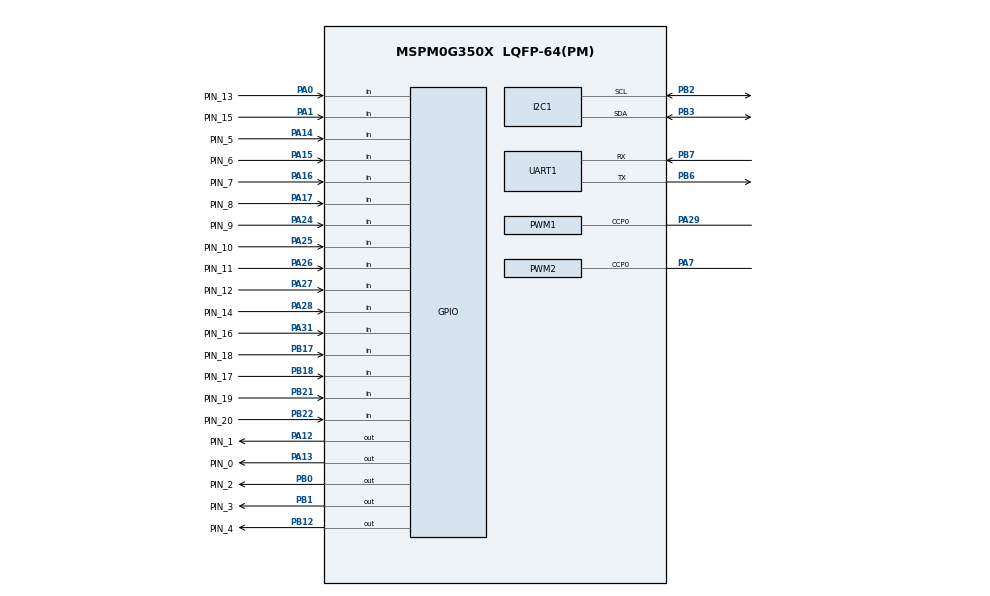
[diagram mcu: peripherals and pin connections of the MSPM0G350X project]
/**
 * @cliArgs --device "MSPM0G350X" --part "Default" --package "LQFP-64(PM)" --product "mspm0_sdk@2.10.00.04"
 * @versions {"tool":"1.26.2+4477"}
 */

/**
 * Import the modules used in this configuration.
 */
const GPIO   = scripting.addModule("/ti/driverlib/GPIO", {}, false);
const GPIO1  = GPIO.addInstance();
const GPIO2  = GPIO.addInstance();
const GPIO3  = GPIO.addInstance();
const GPIO4  = GPIO.addInstance();
const GPIO5  = GPIO.addInstance();
const GPIO6  = GPIO.addInstance();
const GPIO7  = GPIO.addInstance();
const GPIO8  = GPIO.addInstance();
const GPIO9  = GPIO.addInstance();
const GPIO10 = GPIO.addInstance();
const GPIO11 = GPIO.addInstance();
const GPIO12 = GPIO.addInstance();
const GPIO13 = GPIO.addInstance();
const GPIO14 = GPIO.addInstance();
const GPIO15 = GPIO.addInstance();
const GPIO16 = GPIO.addInstance();
const GPIO17 = GPIO.addInstance();
const GPIO18 = GPIO.addInstance();
const GPIO19 = GPIO.addInstance();
const GPIO20 = GPIO.addInstance();
const GPIO21 = GPIO.addInstance();
const I2C    = scripting.addModule("/ti/driverlib/I2C", {}, false);
const I2C1   = I2C.addInstance();
const PWM    = scripting.addModule("/ti/driverlib/PWM", {}, false);
const PWM1   = PWM.addInstance();
const PWM2   = PWM.addInstance();
const SYSCTL = scripting.addModule("/ti/driverlib/SYSCTL");
const UART   = scripting.addModule("/ti/driverlib/UART", {}, false);
const UART1  = UART.addInstance();

/**
 * Write custom configuration values to the imported modules.
 */
GPIO1.$name                         = "MOTOR_AIN2";
GPIO1.port                          = "PORTA";
GPIO1.associatedPins[0].$name       = "PIN_0";
GPIO1.associatedPins[0].pin.$assign = "PA13";

const Board = scripting.addModule("/ti/driverlib/Board", {}, false);

GPIO2.$name                         = "MOTOR_AIN1";
GPIO2.port                          = "PORTA";
GPIO2.associatedPins[0].$name       = "PIN_1";
GPIO2.associatedPins[0].pin.$assign = "PA12";

GPIO3.$name                         = "MOTOR_BIN1";
GPIO3.port                          = "PORTB";
GPIO3.associatedPins[0].$name       = "PIN_2";
GPIO3.associatedPins[0].pin.$assign = "PB0";

GPIO4.$name                         = "MOTOR_BIN2";
GPIO4.port                          = "PORTB";
GPIO4.associatedPins[0].$name       = "PIN_3";
GPIO4.associatedPins[0].pin.$assign = "PB1";

GPIO5.$name                         = "MOTOR_STBY";
GPIO5.port                          = "PORTB";
GPIO5.associatedPins[0].$name       = "PIN_4";
GPIO5.associatedPins[0].pin.$assign = "PB12";

GPIO6.$name                         = "SENSOR_S0";
GPIO6.port                          = "PORTA";
GPIO6.associatedPins[0].$name       = "PIN_5";
GPIO6.associatedPins[0].direction   = "INPUT";
GPIO6.associatedPins[0].pin.$assign = "PA14";

GPIO7.$name                         = "SENSOR_S1";
GPIO7.port                          = "PORTA";
GPIO7.associatedPins[0].$name       = "PIN_6";
GPIO7.associatedPins[0].direction   = "INPUT";
GPIO7.associatedPins[0].pin.$assign = "PA15";

GPIO8.$name                         = "SENSOR_S2";
GPIO8.port                          = "PORTA";
GPIO8.associatedPins[0].$name       = "PIN_7";
GPIO8.associatedPins[0].direction   = "INPUT";
GPIO8.associatedPins[0].pin.$assign = "PA16";

GPIO9.$name                         = "SENSOR_S3";
GPIO9.port                          = "PORTA";
GPIO9.associatedPins[0].$name       = "PIN_8";
GPIO9.associatedPins[0].direction   = "INPUT";
GPIO9.associatedPins[0].pin.$assign = "PA17";

GPIO10.$name                         = "SENSOR_S4";
GPIO10.port                          = "PORTA";
GPIO10.associatedPins[0].$name       = "PIN_9";
GPIO10.associatedPins[0].direction   = "INPUT";
GPIO10.associatedPins[0].pin.$assign = "PA24";

GPIO11.$name                         = "SENSOR_S5";
GPIO11.port                          = "PORTA";
GPIO11.associatedPins[0].$name       = "PIN_10";
GPIO11.associatedPins[0].direction   = "INPUT";
GPIO11.associatedPins[0].pin.$assign = "PA25";

GPIO12.$name                         = "SENSOR_S6";
GPIO12.port                          = "PORTA";
GPIO12.associatedPins[0].$name       = "PIN_11";
GPIO12.associatedPins[0].direction   = "INPUT";
GPIO12.associatedPins[0].pin.$assign = "PA26";

GPIO13.$name                         = "SENSOR_S7";
GPIO13.port                          = "PORTA";
GPIO13.associatedPins[0].$name       = "PIN_12";
GPIO13.associatedPins[0].direction   = "INPUT";
GPIO13.associatedPins[0].pin.$assign = "PA27";

GPIO14.$name                         = "SENSOR_S8";
GPIO14.port                          = "PORTA";
GPIO14.associatedPins[0].$name       = "PIN_13";
GPIO14.associatedPins[0].direction   = "INPUT";
GPIO14.associatedPins[0].pin.$assign = "PA0";

GPIO15.$name                         = "SENSOR_S9";
GPIO15.port                          = "PORTA";
GPIO15.associatedPins[0].$name       = "PIN_14";
GPIO15.associatedPins[0].direction   = "INPUT";
GPIO15.associatedPins[0].pin.$assign = "PA28";

GPIO16.$name                         = "SENSOR_S10";
GPIO16.port                          = "PORTA";
GPIO16.associatedPins[0].$name       = "PIN_15";
GPIO16.associatedPins[0].direction   = "INPUT";
GPIO16.associatedPins[0].pin.$assign = "PA1";

GPIO17.$name                         = "SENSOR_S11";
GPIO17.port                          = "PORTA";
GPIO17.associatedPins[0].$name       = "PIN_16";
GPIO17.associatedPins[0].direction   = "INPUT";
GPIO17.associatedPins[0].pin.$assign = "PA31";

GPIO18.$name                                 = "ENC_LEFT_A";
GPIO18.port                                  = "PORTB";
GPIO18.associatedPins[0].$name               = "PIN_17";
GPIO18.associatedPins[0].direction           = "INPUT";
GPIO18.associatedPins[0].assignedPortSegment = "Upper";
GPIO18.associatedPins[0].pin.$assign         = "PB18";

GPIO19.$name                                 = "ENC_LEFT_B";
GPIO19.port                                  = "PORTB";
GPIO19.associatedPins[0].$name               = "PIN_18";
GPIO19.associatedPins[0].direction           = "INPUT";
GPIO19.associatedPins[0].assignedPortSegment = "Upper";
GPIO19.associatedPins[0].pin.$assign         = "PB17";

GPIO20.$name                                 = "ENC_RIGHT_A";
GPIO20.port                                  = "PORTB";
GPIO20.associatedPins[0].$name               = "PIN_19";
GPIO20.associatedPins[0].direction           = "INPUT";
GPIO20.associatedPins[0].assignedPortSegment = "Upper";
GPIO20.associatedPins[0].pin.$assign         = "PB21";

GPIO21.$name                                 = "ENC_RIGHT_B";
GPIO21.port                                  = "PORTB";
GPIO21.associatedPins[0].$name               = "PIN_20";
GPIO21.associatedPins[0].direction           = "INPUT";
GPIO21.associatedPins[0].assignedPortSegment = "Upper";
GPIO21.associatedPins[0].pin.$assign         = "PB22";

I2C1.$name                             = "I2C_Sensor";
I2C1.basicEnableController             = true;
I2C1.basicControllerStandardBusSpeed   = "Fast";
I2C1.peripheral.sdaPin.$assign         = "PB3";
I2C1.peripheral.sclPin.$assign         = "PB2";
I2C1.sdaPinConfig.hideOutputInversion  = scripting.forceWrite(false);
I2C1.sdaPinConfig.onlyInternalResistor = scripting.forceWrite(false);
I2C1.sdaPinConfig.passedPeripheralType = scripting.forceWrite("Digital");
I2C1.sdaPinConfig.$name                = "ti_driverlib_gpio_GPIOPinGeneric4";
I2C1.sclPinConfig.hideOutputInversion  = scripting.forceWrite(false);
I2C1.sclPinConfig.onlyInternalResistor = scripting.forceWrite(false);
I2C1.sclPinConfig.passedPeripheralType = scripting.forceWrite("Digital");
I2C1.sclPinConfig.$name                = "ti_driverlib_gpio_GPIOPinGeneric5";

PWM1.$name                              = "MotorPWM_Left";
PWM1.timerCount                         = 1600;
PWM1.ccIndex                            = [0];
PWM1.PWM_CHANNEL_0.$name                = "ti_driverlib_pwm_PWMTimerCC0";
PWM1.ccp0PinConfig.direction            = scripting.forceWrite("OUTPUT");
PWM1.ccp0PinConfig.hideOutputInversion  = scripting.forceWrite(false);
PWM1.ccp0PinConfig.onlyInternalResistor = scripting.forceWrite(false);
PWM1.ccp0PinConfig.passedPeripheralType = scripting.forceWrite("Digital");
PWM1.ccp0PinConfig.$name                = "ti_driverlib_gpio_GPIOPinGeneric0";
PWM1.peripheral.ccp0Pin.$assign         = "PA29";

PWM2.$name                              = "MotorPWM_Right";
PWM2.timerCount                         = 1600;
PWM2.ccIndex                            = [0];
PWM2.PWM_CHANNEL_0.$name                = "ti_driverlib_pwm_PWMTimerCC1";
PWM2.ccp0PinConfig.direction            = scripting.forceWrite("OUTPUT");
PWM2.ccp0PinConfig.hideOutputInversion  = scripting.forceWrite(false);
PWM2.ccp0PinConfig.onlyInternalResistor = scripting.forceWrite(false);
PWM2.ccp0PinConfig.passedPeripheralType = scripting.forceWrite("Digital");
PWM2.ccp0PinConfig.$name                = "ti_driverlib_gpio_GPIOPinGeneric1";
PWM2.peripheral.ccp0Pin.$assign         = "PA7";

SYSCTL.forceDefaultClkConfig = true;

UART1.$name                            = "PID_UART";
UART1.targetBaudRate                   = 115200;
UART1.peripheral.rxPin.$assign         = "PB7";
UART1.peripheral.txPin.$assign         = "PB6";
UART1.txPinConfig.direction            = scripting.forceWrite("OUTPUT");
UART1.txPinConfig.hideOutputInversion  = scripting.forceWrite(false);
UART1.txPinConfig.onlyInternalResistor = scripting.forceWrite(false);
UART1.txPinConfig.passedPeripheralType = scripting.forceWrite("Digital");
UART1.txPinConfig.$name                = "ti_driverlib_gpio_GPIOPinGeneric2";
UART1.rxPinConfig.hideOutputInversion  = scripting.forceWrite(false);
UART1.rxPinConfig.onlyInternalResistor = scripting.forceWrite(false);
UART1.rxPinConfig.passedPeripheralType = scripting.forceWrite("Digital");
UART1.rxPinConfig.$name                = "ti_driverlib_gpio_GPIOPinGeneric3";

/**
 * Pinmux solution for unlocked pins/peripherals. This ensures that minor changes to the automatic solver in a future
 * version of the tool will not impact the pinmux you originally saw.  These lines can be completely deleted in order to
 * re-solve from scratch.
 */
Board.peripheral.$suggestSolution          = "DEBUGSS";
Board.peripheral.swclkPin.$suggestSolution = "PA20";
Board.peripheral.swdioPin.$suggestSolution = "PA19";
I2C1.peripheral.$suggestSolution           = "I2C1";
PWM1.peripheral.$suggestSolution           = "TIMG6";
PWM2.peripheral.$suggestSolution           = "TIMG8";
SYSCTL.peripheral.$suggestSolution         = "SYSCTL";
UART1.peripheral.$suggestSolution          = "UART1";
